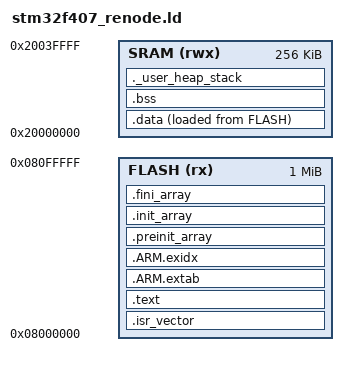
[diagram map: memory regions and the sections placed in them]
/*******************************************************************************
 * Copyright (c) 2025 Vinicius Tadeu Zein
 *
 * SPDX-License-Identifier: Apache-2.0
 *
 * Linker script for STM32F407 on Renode.
 * Flash: 1MB at 0x08000000, SRAM: 256KB at 0x20000000.
 * Real STM32F407 has 192KB SRAM + 64KB CCM; Renode maps a contiguous
 * 256KB block which is sufficient for test binaries.
 ******************************************************************************/

MEMORY
{
    FLASH (rx)  : ORIGIN = 0x08000000, LENGTH = 1024K
    SRAM  (rwx) : ORIGIN = 0x20000000, LENGTH = 256K
}

_estack = ORIGIN(SRAM) + LENGTH(SRAM);

ENTRY(Reset_Handler)

SECTIONS
{
    .isr_vector :
    {
        . = ALIGN(4);
        KEEP(*(.isr_vector))
        . = ALIGN(4);
    } > FLASH

    .text :
    {
        . = ALIGN(4);
        *(.text)
        *(.text*)
        *(.rodata)
        *(.rodata*)
        *(.glue_7)
        *(.glue_7t)
        KEEP(*(.init))
        KEEP(*(.fini))
        . = ALIGN(4);
        _etext = .;
    } > FLASH

    .ARM.extab :
    {
        *(.ARM.extab* .gnu.linkonce.armextab.*)
    } > FLASH

    .ARM.exidx :
    {
        __exidx_start = .;
        *(.ARM.exidx* .gnu.linkonce.armexidx.*)
        __exidx_end = .;
    } > FLASH

    .preinit_array :
    {
        PROVIDE_HIDDEN(__preinit_array_start = .);
        KEEP(*(.preinit_array*))
        PROVIDE_HIDDEN(__preinit_array_end = .);
    } > FLASH

    .init_array :
    {
        PROVIDE_HIDDEN(__init_array_start = .);
        KEEP(*(SORT(.init_array.*)))
        KEEP(*(.init_array*))
        PROVIDE_HIDDEN(__init_array_end = .);
    } > FLASH

    .fini_array :
    {
        PROVIDE_HIDDEN(__fini_array_start = .);
        KEEP(*(SORT(.fini_array.*)))
        KEEP(*(.fini_array*))
        PROVIDE_HIDDEN(__fini_array_end = .);
    } > FLASH

    _sidata = LOADADDR(.data);

    .data :
    {
        . = ALIGN(4);
        _sdata = .;
        *(.data)
        *(.data*)
        . = ALIGN(4);
        _edata = .;
    } > SRAM AT> FLASH

    .bss :
    {
        . = ALIGN(4);
        _sbss = .;
        __bss_start__ = _sbss;
        *(.bss)
        *(.bss*)
        *(COMMON)
        . = ALIGN(4);
        _ebss = .;
        __bss_end__ = _ebss;
    } > SRAM

    ._user_heap_stack :
    {
        . = ALIGN(8);
        PROVIDE(end = .);
        PROVIDE(_end = .);
        . = . + 0x10000; /* 64KB heap */
        PROVIDE(__heap_limit__ = .);
        . = . + 0x4000;  /* 16KB stack */
        . = ALIGN(8);
    } > SRAM
}
